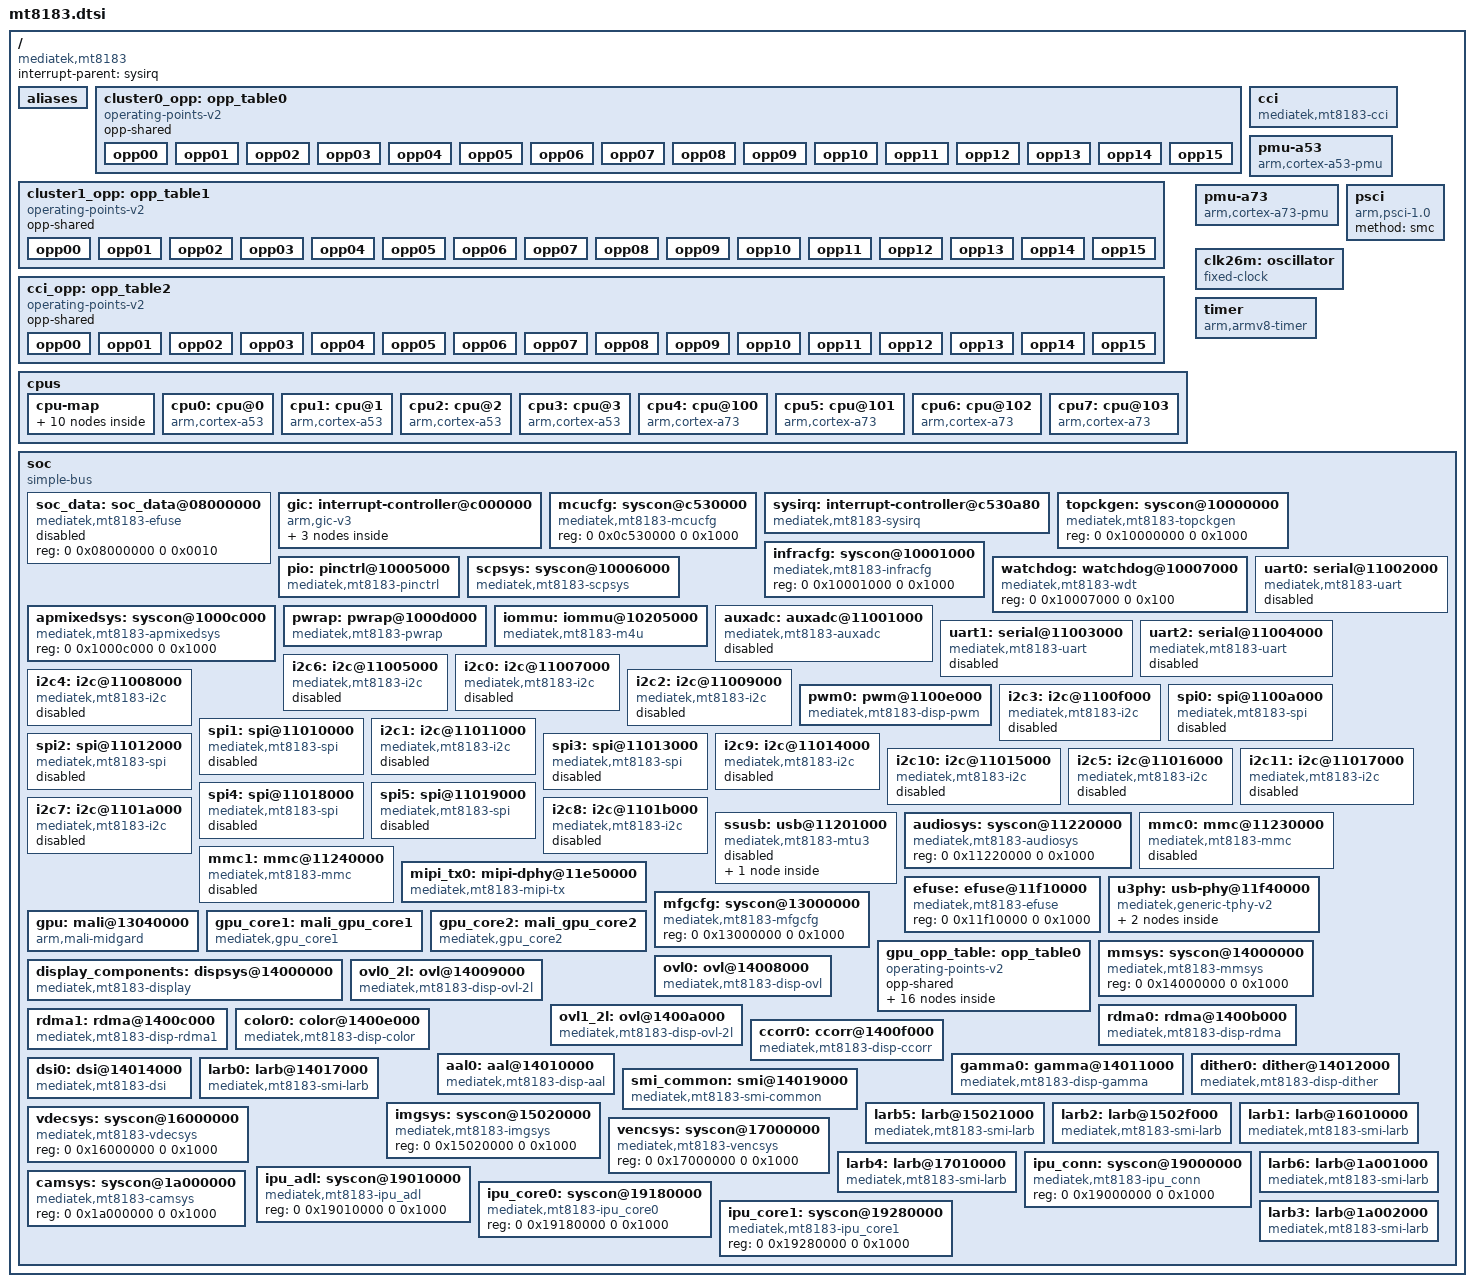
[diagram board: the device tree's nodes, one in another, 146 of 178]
// SPDX-License-Identifier: (GPL-2.0 OR MIT)
/*
 * Copyright (c) 2018 MediaTek Inc.
 * Author: Ben Ho <ben.ho@mediatek.com>
 *	   Erin Lo <erin.lo@mediatek.com>
 */

#include <dt-bindings/clock/mt8183-clk.h>
#include <dt-bindings/interrupt-controller/arm-gic.h>
#include <dt-bindings/interrupt-controller/irq.h>
#include <dt-bindings/memory/mt8183-larb-port.h>
#include <dt-bindings/phy/phy.h>
#include <dt-bindings/power/mt8183-power.h>
#include <dt-bindings/reset-controller/mt8183-resets.h>
#include "mt8183-pinfunc.h"

/ {
	compatible = "mediatek,mt8183";
	interrupt-parent = <&sysirq>;
	#address-cells = <2>;
	#size-cells = <2>;

	aliases {
		ovl0 = &ovl0;
		ovl_2l0 = &ovl0_2l;
		ovl_2l1 = &ovl1_2l;
		rdma0 = &rdma0;
		rdma1 = &rdma1;
		i2c0 = &i2c0;
		i2c1 = &i2c1;
		i2c2 = &i2c2;
		i2c3 = &i2c3;
		i2c4 = &i2c4;
		i2c5 = &i2c5;
		i2c6 = &i2c6;
		i2c7 = &i2c7;
		i2c8 = &i2c8;
		i2c9 = &i2c9;
		i2c10 = &i2c10;
		i2c11 = &i2c11;
	};

	cluster0_opp: opp_table0 {
		compatible = "operating-points-v2";
		opp-shared;
		opp00 {
			opp-hz = /bits/ 64 <793000000>;
			opp-microvolt = <650000>;
		};
		opp01 {
			opp-hz = /bits/ 64 <910000000>;
			opp-microvolt = <687500>;
		};
		opp02 {
			opp-hz = /bits/ 64 <1014000000>;
			opp-microvolt = <718750>;
		};
		opp03 {
			opp-hz = /bits/ 64 <1131000000>;
			opp-microvolt = <756250>;
		};
		opp04 {
			opp-hz = /bits/ 64 <1248000000>;
			opp-microvolt = <800000>;
		};
		opp05 {
			opp-hz = /bits/ 64 <1326000000>;
			opp-microvolt = <818750>;
		};
		opp06 {
			opp-hz = /bits/ 64 <1417000000>;
			opp-microvolt = <850000>;
		};
		opp07 {
			opp-hz = /bits/ 64 <1508000000>;
			opp-microvolt = <868750>;
		};
		opp08 {
			opp-hz = /bits/ 64 <1586000000>;
			opp-microvolt = <893750>;
		};
		opp09 {
			opp-hz = /bits/ 64 <1625000000>;
			opp-microvolt = <906250>;
		};
		opp10 {
			opp-hz = /bits/ 64 <1677000000>;
			opp-microvolt = <931250>;
		};
		opp11 {
			opp-hz = /bits/ 64 <1716000000>;
			opp-microvolt = <943750>;
		};
		opp12 {
			opp-hz = /bits/ 64 <1781000000>;
			opp-microvolt = <975000>;
		};
		opp13 {
			opp-hz = /bits/ 64 <1846000000>;
			opp-microvolt = <1000000>;
		};
		opp14 {
			opp-hz = /bits/ 64 <1924000000>;
			opp-microvolt = <1025000>;
		};
		opp15 {
			opp-hz = /bits/ 64 <1989000000>;
			opp-microvolt = <1050000>;
		};	};

	cluster1_opp: opp_table1 {
		compatible = "operating-points-v2";
		opp-shared;
		opp00 {
			opp-hz = /bits/ 64 <793000000>;
			opp-microvolt = <650000>;
		};
		opp01 {
			opp-hz = /bits/ 64 <910000000>;
			opp-microvolt = <675000>;
		};
		opp02 {
			opp-hz = /bits/ 64 <1014000000>;
			opp-microvolt = <700000>;
		};
		opp03 {
			opp-hz = /bits/ 64 <1131000000>;
			opp-microvolt = <725000>;
		};
		opp04 {
			opp-hz = /bits/ 64 <1248000000>;
			opp-microvolt = <750000>;
		};
		opp05 {
			opp-hz = /bits/ 64 <1326000000>;
			opp-microvolt = <775000>;
		};
		opp06 {
			opp-hz = /bits/ 64 <1417000000>;
			opp-microvolt = <800000>;
		};
		opp07 {
			opp-hz = /bits/ 64 <1508000000>;
			opp-microvolt = <825000>;
		};
		opp08 {
			opp-hz = /bits/ 64 <1586000000>;
			opp-microvolt = <850000>;
		};
		opp09 {
			opp-hz = /bits/ 64 <1625000000>;
			opp-microvolt = <862500>;
		};
		opp10 {
			opp-hz = /bits/ 64 <1677000000>;
			opp-microvolt = <881250>;
		};
		opp11 {
			opp-hz = /bits/ 64 <1716000000>;
			opp-microvolt = <900000>;
		};
		opp12 {
			opp-hz = /bits/ 64 <1781000000>;
			opp-microvolt = <925000>;
		};
		opp13 {
			opp-hz = /bits/ 64 <1846000000>;
			opp-microvolt = <950000>;
		};
		opp14 {
			opp-hz = /bits/ 64 <1924000000>;
			opp-microvolt = <975000>;
		};
		opp15 {
			opp-hz = /bits/ 64 <1989000000>;
			opp-microvolt = <1000000>;
		};
	};

	cci_opp: opp_table2 {
		compatible = "operating-points-v2";
		opp-shared;
		opp00 {
			opp-hz = /bits/ 64 <273000000>;
			opp-microvolt = <650000>;
		};
		opp01 {
			opp-hz = /bits/ 64 <338000000>;
			opp-microvolt = <687500>;
		};
		opp02 {
			opp-hz = /bits/ 64 <403000000>;
			opp-microvolt = <718750>;
		};
		opp03 {
			opp-hz = /bits/ 64 <463000000>;
			opp-microvolt = <756250>;
		};
		opp04 {
			opp-hz = /bits/ 64 <546000000>;
			opp-microvolt = <800000>;
		};
		opp05 {
			opp-hz = /bits/ 64 <624000000>;
			opp-microvolt = <818750>;
		};
		opp06 {
			opp-hz = /bits/ 64 <689000000>;
			opp-microvolt = <850000>;
		};
		opp07 {
			opp-hz = /bits/ 64 <767000000>;
			opp-microvolt = <868750>;
		};
		opp08 {
			opp-hz = /bits/ 64 <845000000>;
			opp-microvolt = <893750>;
		};
		opp09 {
			opp-hz = /bits/ 64 <871000000>;
			opp-microvolt = <906250>;
		};
		opp10 {
			opp-hz = /bits/ 64 <923000000>;
			opp-microvolt = <931250>;
		};
		opp11 {
			opp-hz = /bits/ 64 <962000000>;
			opp-microvolt = <943750>;
		};
		opp12 {
			opp-hz = /bits/ 64 <1027000000>;
			opp-microvolt = <975000>;
		};
		opp13 {
			opp-hz = /bits/ 64 <1092000000>;
			opp-microvolt = <1000000>;
		};
		opp14 {
			opp-hz = /bits/ 64 <1144000000>;
			opp-microvolt = <1025000>;
		};
		opp15 {
			opp-hz = /bits/ 64 <1196000000>;
			opp-microvolt = <1050000>;
		};
	};

	cci: cci {
		compatible = "mediatek,mt8183-cci";
		clocks = <&apmixedsys CLK_APMIXED_CCIPLL>;
		clock-names = "cci_clock";
		operating-points-v2 = <&cci_opp>;
	};

	cpus {
		#address-cells = <1>;
		#size-cells = <0>;

		cpu-map {
			cluster0 {
				core0 {
					cpu = <&cpu0>;
				};
				core1 {
					cpu = <&cpu1>;
				};
				core2 {
					cpu = <&cpu2>;
				};
				core3 {
					cpu = <&cpu3>;
				};
			};

			cluster1 {
				core0 {
					cpu = <&cpu4>;
				};
				core1 {
					cpu = <&cpu5>;
				};
				core2 {
					cpu = <&cpu6>;
				};
				core3 {
					cpu = <&cpu7>;
				};
			};
		};

		cpu0: cpu@0 {
			device_type = "cpu";
			compatible = "arm,cortex-a53";
			reg = <0x000>;
			enable-method = "psci";
			clocks = <&mcucfg CLK_MCU_MP0_SEL>,
				 <&topckgen CLK_TOP_ARMPLL_DIV_PLL1>;
			clock-names = "cpu", "intermediate";
			operating-points-v2 = <&cluster0_opp>;
		};

		cpu1: cpu@1 {
			device_type = "cpu";
			compatible = "arm,cortex-a53";
			reg = <0x001>;
			enable-method = "psci";
			clocks = <&mcucfg CLK_MCU_MP0_SEL>,
				 <&topckgen CLK_TOP_ARMPLL_DIV_PLL1>;
			clock-names = "cpu", "intermediate";
			operating-points-v2 = <&cluster0_opp>;
		};

		cpu2: cpu@2 {
			device_type = "cpu";
			compatible = "arm,cortex-a53";
			reg = <0x002>;
			enable-method = "psci";
			clocks = <&mcucfg CLK_MCU_MP0_SEL>,
				 <&topckgen CLK_TOP_ARMPLL_DIV_PLL1>;
			clock-names = "cpu", "intermediate";
			operating-points-v2 = <&cluster0_opp>;
		};

		cpu3: cpu@3 {
			device_type = "cpu";
			compatible = "arm,cortex-a53";
			reg = <0x003>;
			enable-method = "psci";
			clocks = <&mcucfg CLK_MCU_MP0_SEL>,
				 <&topckgen CLK_TOP_ARMPLL_DIV_PLL1>;
			clock-names = "cpu", "intermediate";
			operating-points-v2 = <&cluster0_opp>;
		};

		cpu4: cpu@100 {
			device_type = "cpu";
			compatible = "arm,cortex-a73";
			reg = <0x100>;
			enable-method = "psci";
			clocks = <&mcucfg CLK_MCU_MP2_SEL>,
				 <&topckgen CLK_TOP_ARMPLL_DIV_PLL1>;
			clock-names = "cpu", "intermediate";
			operating-points-v2 = <&cluster1_opp>;
		};

		cpu5: cpu@101 {
			device_type = "cpu";
			compatible = "arm,cortex-a73";
			reg = <0x101>;
			enable-method = "psci";
			clocks = <&mcucfg CLK_MCU_MP2_SEL>,
				 <&topckgen CLK_TOP_ARMPLL_DIV_PLL1>;
			clock-names = "cpu", "intermediate";
			operating-points-v2 = <&cluster1_opp>;
		};

		cpu6: cpu@102 {
			device_type = "cpu";
			compatible = "arm,cortex-a73";
			reg = <0x102>;
			enable-method = "psci";
			clocks = <&mcucfg CLK_MCU_MP2_SEL>,
				 <&topckgen CLK_TOP_ARMPLL_DIV_PLL1>;
			clock-names = "cpu", "intermediate";
			operating-points-v2 = <&cluster1_opp>;
		};

		cpu7: cpu@103 {
			device_type = "cpu";
			compatible = "arm,cortex-a73";
			reg = <0x103>;
			enable-method = "psci";
			clocks = <&mcucfg CLK_MCU_MP2_SEL>,
				 <&topckgen CLK_TOP_ARMPLL_DIV_PLL1>;
			clock-names = "cpu", "intermediate";
			operating-points-v2 = <&cluster1_opp>;
		};
	};

	pmu-a53 {
		compatible = "arm,cortex-a53-pmu";
		interrupt-parent = <&gic>;
		interrupts = <GIC_PPI 7 IRQ_TYPE_LEVEL_LOW &ppi_cluster0>;
	};

	pmu-a73 {
		compatible = "arm,cortex-a73-pmu";
		interrupt-parent = <&gic>;
		interrupts = <GIC_PPI 7 IRQ_TYPE_LEVEL_LOW &ppi_cluster1>;
	};

	psci {
		compatible      = "arm,psci-1.0";
		method          = "smc";
	};

	clk26m: oscillator {
		compatible = "fixed-clock";
		#clock-cells = <0>;
		clock-frequency = <26000000>;
		clock-output-names = "clk26m";
	};

	timer {
		compatible = "arm,armv8-timer";
		interrupt-parent = <&gic>;
		interrupts = <GIC_PPI 13 IRQ_TYPE_LEVEL_LOW 0>,
			     <GIC_PPI 14 IRQ_TYPE_LEVEL_LOW 0>,
			     <GIC_PPI 11 IRQ_TYPE_LEVEL_LOW 0>,
			     <GIC_PPI 10 IRQ_TYPE_LEVEL_LOW 0>;
	};

	soc {
		#address-cells = <2>;
		#size-cells = <2>;
		compatible = "simple-bus";
		ranges;

		soc_data: soc_data@08000000 {
			compatible = "mediatek,mt8183-efuse",
				     "mediatek,efuse";
			reg = <0 0x08000000 0 0x0010>;
			#address-cells = <1>;
			#size-cells = <1>;
			status = "disabled";
		};

		gic: interrupt-controller@c000000 {
			compatible = "arm,gic-v3";
			#interrupt-cells = <4>;
			interrupt-parent = <&gic>;
			interrupt-controller;
			reg = <0 0x0c000000 0 0x40000>,  /* GICD */
			      <0 0x0c100000 0 0x200000>, /* GICR */
			      <0 0x0c400000 0 0x2000>,   /* GICC */
			      <0 0x0c410000 0 0x1000>,   /* GICH */
			      <0 0x0c420000 0 0x2000>;   /* GICV */

			interrupts = <GIC_PPI 9 IRQ_TYPE_LEVEL_HIGH 0>;
			ppi-partitions {
				ppi_cluster0: interrupt-partition-0 {
					affinity = <&cpu0 &cpu1 &cpu2 &cpu3>;
				};
				ppi_cluster1: interrupt-partition-1 {
					affinity = <&cpu4 &cpu5 &cpu6 &cpu7>;
				};
			};
		};

		mcucfg: syscon@c530000 {
			compatible = "mediatek,mt8183-mcucfg", "syscon";
			reg = <0 0x0c530000 0 0x1000>;
			#clock-cells = <1>;
		};

		sysirq: interrupt-controller@c530a80 {
			compatible = "mediatek,mt8183-sysirq",
				     "mediatek,mt6577-sysirq";
			interrupt-controller;
			#interrupt-cells = <3>;
			interrupt-parent = <&gic>;
			reg = <0 0x0c530a80 0 0x50>;
		};

		topckgen: syscon@10000000 {
			compatible = "mediatek,mt8183-topckgen", "syscon";
			reg = <0 0x10000000 0 0x1000>;
			#clock-cells = <1>;
		};

		infracfg: syscon@10001000 {
			compatible = "mediatek,mt8183-infracfg", "syscon";
			reg = <0 0x10001000 0 0x1000>;
			#clock-cells = <1>;
			#reset-cells = <1>;
		};

		pio: pinctrl@10005000 {
			compatible = "mediatek,mt8183-pinctrl";
			reg = <0 0x10005000 0 0x1000>,
			      <0 0x11f20000 0 0x1000>,
			      <0 0x11e80000 0 0x1000>,
			      <0 0x11e70000 0 0x1000>,
			      <0 0x11e90000 0 0x1000>,
			      <0 0x11d30000 0 0x1000>,
			      <0 0x11d20000 0 0x1000>,
			      <0 0x11c50000 0 0x1000>,
			      <0 0x11f30000 0 0x1000>,
			      <0 0x1000b000 0 0x1000>;
			reg-names = "iocfg0", "iocfg1", "iocfg2",
				    "iocfg3", "iocfg4", "iocfg5",
				    "iocfg6", "iocfg7", "iocfg8",
				    "eint";
			gpio-controller;
			#gpio-cells = <2>;
			gpio-ranges = <&pio 0 0 192>;
			interrupt-controller;
			interrupts = <GIC_SPI 177 IRQ_TYPE_LEVEL_HIGH>;
			#interrupt-cells = <2>;
		};

		scpsys: syscon@10006000 {
			compatible = "mediatek,mt8183-scpsys", "syscon";
			#power-domain-cells = <1>;
			reg = <0 0x10006000 0 0x1000>;
			clocks = <&topckgen CLK_TOP_MUX_AUD_INTBUS>,
				 <&infracfg CLK_INFRA_AUDIO>,
				 <&infracfg CLK_INFRA_AUDIO_26M_BCLK>,
				 <&topckgen CLK_TOP_MUX_MFG>,
				 <&topckgen CLK_TOP_MUX_MM>,
				 <&topckgen CLK_TOP_MUX_CAM>,
				 <&topckgen CLK_TOP_MUX_IMG>,
				 <&topckgen CLK_TOP_MUX_IPU_IF>,
				 <&topckgen CLK_TOP_MUX_DSP>,
				 <&topckgen CLK_TOP_MUX_DSP1>,
				 <&topckgen CLK_TOP_MUX_DSP2>,
				 <&mmsys CLK_MM_SMI_COMMON>,
				 <&mmsys CLK_MM_SMI_LARB0>,
				 <&mmsys CLK_MM_SMI_LARB1>,
				 <&mmsys CLK_MM_GALS_COMM0>,
				 <&mmsys CLK_MM_GALS_COMM1>,
				 <&mmsys CLK_MM_GALS_CCU2MM>,
				 <&mmsys CLK_MM_GALS_IPU12MM>,
				 <&mmsys CLK_MM_GALS_IMG2MM>,
				 <&mmsys CLK_MM_GALS_CAM2MM>,
				 <&mmsys CLK_MM_GALS_IPU2MM>,
				 <&imgsys CLK_IMG_LARB5>,
				 <&imgsys CLK_IMG_LARB2>,
				 <&camsys CLK_CAM_LARB6>,
				 <&camsys CLK_CAM_LARB3>,
				 <&camsys CLK_CAM_SENINF>,
				 <&camsys CLK_CAM_CAMSV0>,
				 <&camsys CLK_CAM_CAMSV1>,
				 <&camsys CLK_CAM_CAMSV2>,
				 <&camsys CLK_CAM_CCU>,
				 <&ipu_conn CLK_IPU_CONN_IPU>,
				 <&ipu_conn CLK_IPU_CONN_AHB>,
				 <&ipu_conn CLK_IPU_CONN_AXI>,
				 <&ipu_conn CLK_IPU_CONN_ISP>,
				 <&ipu_conn CLK_IPU_CONN_CAM_ADL>,
				 <&ipu_conn CLK_IPU_CONN_IMG_ADL>;
			clock-names = "audio", "audio1", "audio2",
				      "mfg", "mm", "cam",
				      "isp", "vpu", "vpu1",
				      "vpu2", "vpu3", "mm-0",
				      "mm-1", "mm-2", "mm-3",
				      "mm-4", "mm-5", "mm-6",
				      "mm-7", "mm-8", "mm-9",
				      "isp-0", "isp-1", "cam-0",
				      "cam-1", "cam-2", "cam-3",
				      "cam-4", "cam-5", "cam-6",
				      "vpu-0", "vpu-1", "vpu-2",
				      "vpu-3", "vpu-4", "vpu-5";
			infracfg = <&infracfg>;
			smi_comm = <&smi_common>;
		};

		watchdog: watchdog@10007000 {
			compatible = "mediatek,mt8183-wdt",
				      "mediatek,mt6589-wdt";
			reg = <0 0x10007000 0 0x100>;
		};

		apmixedsys: syscon@1000c000 {
			compatible = "mediatek,mt8183-apmixedsys", "syscon";
			reg = <0 0x1000c000 0 0x1000>;
			#clock-cells = <1>;
		};

		pwrap: pwrap@1000d000 {
			compatible = "mediatek,mt8183-pwrap";
			reg = <0 0x1000d000 0 0x1000>;
			reg-names = "pwrap";
			interrupts = <GIC_SPI 209 IRQ_TYPE_LEVEL_HIGH>;
			clocks = <&topckgen CLK_TOP_MUX_PMICSPI>,
				 <&infracfg CLK_INFRA_PMIC_AP>;
			clock-names = "spi", "wrap";
		};

		iommu: iommu@10205000 {
			compatible = "mediatek,mt8183-m4u";
			reg = <0 0x10205000 0 0x1000>;
			interrupts = <GIC_SPI 166 IRQ_TYPE_LEVEL_LOW>;
			mediatek,larbs = <&larb0 &larb1 &larb2 &larb3
					  &larb4 &larb5 &larb6>;
			#iommu-cells = <1>;
		};

		auxadc: auxadc@11001000 {
			compatible = "mediatek,mt8183-auxadc",
				     "mediatek,mt8173-auxadc";
			reg = <0 0x11001000 0 0x1000>;
			clocks = <&infracfg CLK_INFRA_AUXADC>;
			clock-names = "main";
			#io-channel-cells = <1>;
			status = "disabled";
		};

		uart0: serial@11002000 {
			compatible = "mediatek,mt8183-uart",
				     "mediatek,mt6577-uart";
			reg = <0 0x11002000 0 0x1000>;
			interrupts = <GIC_SPI 91 IRQ_TYPE_LEVEL_LOW>;
			clocks = <&clk26m>, <&infracfg CLK_INFRA_UART0>;
			clock-names = "baud", "bus";
			status = "disabled";
		};

		uart1: serial@11003000 {
			compatible = "mediatek,mt8183-uart",
				     "mediatek,mt6577-uart";
			reg = <0 0x11003000 0 0x1000>;
			interrupts = <GIC_SPI 92 IRQ_TYPE_LEVEL_LOW>;
			clocks = <&clk26m>, <&infracfg CLK_INFRA_UART1>;
			clock-names = "baud", "bus";
			status = "disabled";
		};

		uart2: serial@11004000 {
			compatible = "mediatek,mt8183-uart",
				     "mediatek,mt6577-uart";
			reg = <0 0x11004000 0 0x1000>;
			interrupts = <GIC_SPI 93 IRQ_TYPE_LEVEL_LOW>;
			clocks = <&clk26m>, <&infracfg CLK_INFRA_UART2>;
			clock-names = "baud", "bus";
			status = "disabled";
		};

		i2c6: i2c@11005000 {
			compatible = "mediatek,mt8183-i2c";
			reg = <0 0x11005000 0 0x1000>,
				<0 0x11000600 0 0x80>;
			interrupts = <GIC_SPI 87 IRQ_TYPE_LEVEL_LOW>;
			clocks = <&infracfg CLK_INFRA_I2C6>,
				 <&infracfg CLK_INFRA_AP_DMA>;
			clock-names = "main", "dma";
			clock-div = <1>;
			#address-cells = <1>;
			#size-cells = <0>;
			status = "disabled";
		};

		i2c0: i2c@11007000 {
			compatible = "mediatek,mt8183-i2c";
			reg = <0 0x11007000 0 0x1000>,
				<0 0x11000080 0 0x80>;
			interrupts = <GIC_SPI 81 IRQ_TYPE_LEVEL_LOW>;
			clocks = <&infracfg CLK_INFRA_I2C0>,
				 <&infracfg CLK_INFRA_AP_DMA>;
			clock-names = "main", "dma";
			clock-div = <1>;
			#address-cells = <1>;
			#size-cells = <0>;
			status = "disabled";
		};

		i2c4: i2c@11008000 {
			compatible = "mediatek,mt8183-i2c";
			id = <4>;
			reg = <0 0x11008000 0 0x1000>,
				<0 0x11000100 0 0x80>;
			interrupts = <GIC_SPI 82 IRQ_TYPE_LEVEL_LOW>;
			clocks = <&infracfg CLK_INFRA_I2C1>,
				 <&infracfg CLK_INFRA_AP_DMA>,
				 <&infracfg CLK_INFRA_I2C1_ARBITER>;
			clock-names = "main", "dma","arb";
			clock-div = <1>;
			#address-cells = <1>;
			#size-cells = <0>;
			status = "disabled";
		};

		i2c2: i2c@11009000 {
			compatible = "mediatek,mt8183-i2c";
			reg = <0 0x11009000 0 0x1000>,
				<0 0x11000280 0 0x80>;
			interrupts = <GIC_SPI 83 IRQ_TYPE_LEVEL_LOW>;
			clocks = <&infracfg CLK_INFRA_I2C2>,
				 <&infracfg CLK_INFRA_AP_DMA>,
				 <&infracfg CLK_INFRA_I2C2_ARBITER>;
			clock-names = "main", "dma", "arb";
			clock-div = <1>;
			#address-cells = <1>;
			#size-cells = <0>;
			status = "disabled";
		};

		pwm0: pwm@1100e000 {
			compatible = "mediatek,mt8183-disp-pwm";
			reg = <0 0x1100e000 0 0x1000>;
			interrupts = <GIC_SPI 128 IRQ_TYPE_LEVEL_LOW>;
			power-domains = <&scpsys MT8183_POWER_DOMAIN_DISP>;
			#pwm-cells = <2>;
			clocks = <&topckgen CLK_TOP_MUX_DISP_PWM>,
					<&infracfg CLK_INFRA_DISP_PWM>;
			clock-names = "main", "mm";
		};

		i2c3: i2c@1100f000 {
			compatible = "mediatek,mt8183-i2c";
			reg = <0 0x1100f000 0 0x1000>,
				<0 0x11000400 0 0x80>;
			interrupts = <GIC_SPI 84 IRQ_TYPE_LEVEL_LOW>;
			clocks = <&infracfg CLK_INFRA_I2C3>,
				 <&infracfg CLK_INFRA_AP_DMA>;
			clock-names = "main", "dma";
			clock-div = <1>;
			#address-cells = <1>;
			#size-cells = <0>;
			status = "disabled";
		};

		spi0: spi@1100a000 {
			compatible = "mediatek,mt8183-spi";
			#address-cells = <1>;
			#size-cells = <0>;
			reg = <0 0x1100a000 0 0x1000>;
			interrupts = <GIC_SPI 120 IRQ_TYPE_LEVEL_LOW>;
			clocks = <&topckgen CLK_TOP_SYSPLL_D5_D2>,
				 <&topckgen CLK_TOP_MUX_SPI>,
				 <&infracfg CLK_INFRA_SPI0>;
			clock-names = "parent-clk", "sel-clk", "spi-clk";
			status = "disabled";
		};

		spi1: spi@11010000 {
			compatible = "mediatek,mt8183-spi";
			#address-cells = <1>;
			#size-cells = <0>;
			reg = <0 0x11010000 0 0x1000>;
			interrupts = <GIC_SPI 124 IRQ_TYPE_LEVEL_LOW>;
			clocks = <&topckgen CLK_TOP_SYSPLL_D5_D2>,
				 <&topckgen CLK_TOP_MUX_SPI>,
				 <&infracfg CLK_INFRA_SPI1>;
			clock-names = "parent-clk", "sel-clk", "spi-clk";
			status = "disabled";
		};

		i2c1: i2c@11011000 {
			compatible = "mediatek,mt8183-i2c";
			reg = <0 0x11011000 0 0x1000>,
				<0 0x11000480 0 0x80>;
			interrupts = <GIC_SPI 85 IRQ_TYPE_LEVEL_LOW>;
			clocks = <&infracfg CLK_INFRA_I2C4>,
				 <&infracfg CLK_INFRA_AP_DMA>;
			clock-names = "main", "dma";
			clock-div = <1>;
			#address-cells = <1>;
			#size-cells = <0>;
			status = "disabled";
		};

		spi2: spi@11012000 {
			compatible = "mediatek,mt8183-spi";
			#address-cells = <1>;
			#size-cells = <0>;
			reg = <0 0x11012000 0 0x1000>;
			interrupts = <GIC_SPI 129 IRQ_TYPE_LEVEL_LOW>;
			clocks = <&topckgen CLK_TOP_SYSPLL_D5_D2>,
				 <&topckgen CLK_TOP_MUX_SPI>,
				 <&infracfg CLK_INFRA_SPI2>;
			clock-names = "parent-clk", "sel-clk", "spi-clk";
			status = "disabled";
		};

		spi3: spi@11013000 {
			compatible = "mediatek,mt8183-spi";
			#address-cells = <1>;
			#size-cells = <0>;
			reg = <0 0x11013000 0 0x1000>;
			interrupts = <GIC_SPI 130 IRQ_TYPE_LEVEL_LOW>;
			clocks = <&topckgen CLK_TOP_SYSPLL_D5_D2>,
				 <&topckgen CLK_TOP_MUX_SPI>,
				 <&infracfg CLK_INFRA_SPI3>;
			clock-names = "parent-clk", "sel-clk", "spi-clk";
			status = "disabled";
		};

		i2c9: i2c@11014000 {
			compatible = "mediatek,mt8183-i2c";
			reg = <0 0x11014000 0 0x1000>,
				<0 0x11000180 0 0x80>;
			interrupts = <GIC_SPI 131 IRQ_TYPE_LEVEL_LOW>;
			clocks = <&infracfg CLK_INFRA_I2C1_IMM>,
				 <&infracfg CLK_INFRA_AP_DMA>,
				 <&infracfg CLK_INFRA_I2C1_ARBITER>;
			clock-names = "main", "dma", "arb";
			clock-div = <1>;
			#address-cells = <1>;
			#size-cells = <0>;
			status = "disabled";
		};

		i2c10: i2c@11015000 {
			compatible = "mediatek,mt8183-i2c";
			reg = <0 0x11015000 0 0x1000>,
				<0 0x11000300 0 0x80>;
			interrupts = <GIC_SPI 132 IRQ_TYPE_LEVEL_LOW>;
			clocks = <&infracfg CLK_INFRA_I2C2_IMM>,
				 <&infracfg CLK_INFRA_AP_DMA>,
				 <&infracfg CLK_INFRA_I2C2_ARBITER>;
			clock-names = "main", "dma", "arb";
			clock-div = <1>;
			#address-cells = <1>;
			#size-cells = <0>;
			status = "disabled";
		};

		i2c5: i2c@11016000 {
			compatible = "mediatek,mt8183-i2c";
			reg = <0 0x11016000 0 0x1000>,
				<0 0x11000500 0 0x80>;
			interrupts = <GIC_SPI 86 IRQ_TYPE_LEVEL_LOW>;
			clocks = <&infracfg CLK_INFRA_I2C5>,
				 <&infracfg CLK_INFRA_AP_DMA>,
				 <&infracfg CLK_INFRA_I2C5_ARBITER>;
			clock-names = "main", "dma", "arb";
			clock-div = <1>;
			#address-cells = <1>;
			#size-cells = <0>;
			status = "disabled";
		};

		i2c11: i2c@11017000 {
			compatible = "mediatek,mt8183-i2c";
			reg = <0 0x11017000 0 0x1000>,
				<0 0x11000580 0 0x80>;
			interrupts = <GIC_SPI 133 IRQ_TYPE_LEVEL_LOW>;
			clocks = <&infracfg CLK_INFRA_I2C5_IMM>,
				 <&infracfg CLK_INFRA_AP_DMA>,
				 <&infracfg CLK_INFRA_I2C5_ARBITER>;
			clock-names = "main", "dma", "arb";
			clock-div = <1>;
			#address-cells = <1>;
			#size-cells = <0>;
			status = "disabled";
		};

		spi4: spi@11018000 {
			compatible = "mediatek,mt8183-spi";
			#address-cells = <1>;
			#size-cells = <0>;
			reg = <0 0x11018000 0 0x1000>;
			interrupts = <GIC_SPI 134 IRQ_TYPE_LEVEL_LOW>;
			clocks = <&topckgen CLK_TOP_SYSPLL_D5_D2>,
				 <&topckgen CLK_TOP_MUX_SPI>,
				 <&infracfg CLK_INFRA_SPI4>;
			clock-names = "parent-clk", "sel-clk", "spi-clk";
			status = "disabled";
		};

		spi5: spi@11019000 {
			compatible = "mediatek,mt8183-spi";
			#address-cells = <1>;
			#size-cells = <0>;
			reg = <0 0x11019000 0 0x1000>;
			interrupts = <GIC_SPI 135 IRQ_TYPE_LEVEL_LOW>;
			clocks = <&topckgen CLK_TOP_SYSPLL_D5_D2>,
				 <&topckgen CLK_TOP_MUX_SPI>,
				 <&infracfg CLK_INFRA_SPI5>;
			clock-names = "parent-clk", "sel-clk", "spi-clk";
			status = "disabled";
		};

		i2c7: i2c@1101a000 {
			compatible = "mediatek,mt8183-i2c";
			reg = <0 0x1101a000 0 0x1000>,
				<0 0x11000680 0 0x80>;
			interrupts = <GIC_SPI 88 IRQ_TYPE_LEVEL_LOW>;
			clocks = <&infracfg CLK_INFRA_I2C7>,
				 <&infracfg CLK_INFRA_AP_DMA>;
			clock-names = "main", "dma";
			clock-div = <1>;
			#address-cells = <1>;
			#size-cells = <0>;
			status = "disabled";
		};

		i2c8: i2c@1101b000 {
			compatible = "mediatek,mt8183-i2c";
			reg = <0 0x1101b000 0 0x1000>,
				<0 0x11000700 0 0x80>;
			interrupts = <GIC_SPI 89 IRQ_TYPE_LEVEL_LOW>;
			clocks = <&infracfg CLK_INFRA_I2C8>,
				 <&infracfg CLK_INFRA_AP_DMA>;
			clock-names = "main", "dma";
			clock-div = <1>;
			#address-cells = <1>;
			#size-cells = <0>;
			status = "disabled";
		};

		ssusb: usb@11201000 {
			compatible ="mediatek,mt8183-mtu3", "mediatek,mtu3";
			reg = <0 0x11201000 0 0x2e00>,
			      <0 0x11203e00 0 0x0100>;
			reg-names = "mac", "ippc";
			interrupts = <GIC_SPI 72 IRQ_TYPE_LEVEL_LOW>;
			phys = <&u2port0 PHY_TYPE_USB2>;
			clocks = <&infracfg CLK_INFRA_UNIPRO_SCK>,
				 <&infracfg CLK_INFRA_USB>;
			clock-names = "sys_ck", "ref_ck";
			#address-cells = <2>;
			#size-cells = <2>;
			ranges;
			status = "disabled";

			usb_host: xhci@11200000 {
				compatible = "mediatek,mtk-xhci";
				reg = <0 0x11200000 0 0x1000>;
				reg-names = "mac";
				interrupts = <GIC_SPI 73 IRQ_TYPE_LEVEL_LOW>;
				clocks = <&infracfg CLK_INFRA_UNIPRO_SCK>,
					 <&infracfg CLK_INFRA_USB>;
				clock-names = "sys_ck", "ref_ck";
				status = "disabled";
			};
		};

		audiosys: syscon@11220000 {
			compatible = "mediatek,mt8183-audiosys", "syscon";
			reg = <0 0x11220000 0 0x1000>;
			#clock-cells = <1>;
		};

		mmc0: mmc@11230000 {
			compatible = "mediatek,mt8183-mmc";
			reg = <0 0x11230000 0 0x1000>,
			      <0 0x11f50000 0 0x1000>;
			interrupts = <GIC_SPI 77 IRQ_TYPE_LEVEL_LOW>;
			clocks = <&topckgen CLK_TOP_MUX_MSDC50_0>,
				 <&infracfg CLK_INFRA_MSDC0>,
				 <&infracfg CLK_INFRA_MSDC0_SCK>;
			clock-names = "source", "hclk", "source_cg";
			status = "disabled";
		};

		mmc1: mmc@11240000 {
			compatible = "mediatek,mt8183-mmc";
			reg = <0 0x11240000 0 0x1000>,
			      <0 0x11e10000 0 0x1000>;
			interrupts = <GIC_SPI 78 IRQ_TYPE_LEVEL_LOW>;
			clocks = <&topckgen CLK_TOP_MUX_MSDC30_1>,
				 <&infracfg CLK_INFRA_MSDC1>,
				 <&infracfg CLK_INFRA_MSDC1_SCK>;
			clock-names = "source", "hclk", "source_cg";
			status = "disabled";
		};

		mipi_tx0: mipi-dphy@11e50000 {
			compatible = "mediatek,mt8183-mipi-tx";
			reg = <0 0x11e50000 0 0x1000>;
			clocks = <&apmixedsys CLK_APMIXED_MIPID0_26M>;
			clock-names = "ref_clk";
			#clock-cells = <0>;
			#phy-cells = <0>;
			clock-output-names = "mipi_tx0_pll";
		};

		efuse: efuse@11f10000 {
			compatible = "mediatek,mt8183-efuse",
				     "mediatek,efuse";
			reg = <0 0x11f10000 0 0x1000>;
		};

		u3phy: usb-phy@11f40000 {
			compatible = "mediatek,generic-tphy-v2";
			#address-cells = <2>;
			#size-cells = <2>;
			ranges;
			status = "okay";

			u2port0: usb-phy@11f40000 {
				reg = <0 0x11f40000 0 0x700>;
				clocks = <&clk26m>;
				clock-names = "ref";
				#phy-cells = <1>;
				status = "okay";
			};

			u3port0: usb-phy@11f40700 {
				reg = <0 0x11f40700 0 0x900>;
				clocks = <&clk26m>;
				clock-names = "ref";
				#phy-cells = <1>;
				status = "okay";
			};
		};

		mfgcfg: syscon@13000000 {
			compatible = "mediatek,mt8183-mfgcfg", "syscon";
			reg = <0 0x13000000 0 0x1000>;
			#clock-cells = <1>;
		};

		gpu: mali@13040000 {
			compatible = "arm,mali-midgard";
			reg = <0 0x13040000 0 0x4000>;
			interrupts =
				<GIC_SPI 278 IRQ_TYPE_LEVEL_LOW>,
				<GIC_SPI 279 IRQ_TYPE_LEVEL_LOW>,
				<GIC_SPI 280 IRQ_TYPE_LEVEL_LOW>;
			interrupt-names = "GPU", "MMU", "JOB";

			clocks =
				<&topckgen CLK_TOP_MFGPLL_CK>,
				<&topckgen CLK_TOP_MUX_MFG>,
				<&clk26m>,
				<&mfgcfg CLK_MFG_BG3D>;
			clock-names =
				"clk_main_parent",
				"clk_mux",
				"clk_sub_parent",
				"subsys_mfg_cg";

			power-domains = <&scpsys MT8183_POWER_DOMAIN_MFG_CORE0>;

			#cooling-cells = <2>;
			cooling-min-level = <0>;
			cooling-max-level = <15>;
		};

		gpu_core1: mali_gpu_core1 {
			compatible = "mediatek,gpu_core1";
			power-domains = <&scpsys MT8183_POWER_DOMAIN_MFG_CORE1>;
		};

		gpu_core2: mali_gpu_core2 {
			compatible = "mediatek,gpu_core2";
			power-domains = <&scpsys MT8183_POWER_DOMAIN_MFG_2D>;
		};

		gpu_opp_table: opp_table0 {
			compatible = "operating-points-v2", "operating-points-v2-mali";
			opp-shared;

			opp-300000000 {
				opp-hz = /bits/ 64 <300000000>;
				opp-microvolt = <625000>, /* Supply 0 */
						<850000>; /* Supply 1 */
				opp-core-mask = /bits/ 64 <0xf>;
			};

			opp-320000000 {
				opp-hz = /bits/ 64 <320000000>;
				opp-microvolt = <631250>, /* Supply 0 */
						<850000>; /* Supply 1 */
				opp-core-mask = /bits/ 64 <0xf>;
			};

			opp-340000000 {
				opp-hz = /bits/ 64 <340000000>;
				opp-microvolt = <637500>, /* Supply 0 */
						<850000>; /* Supply 1 */
				opp-core-mask = /bits/ 64 <0xf>;
			};

			opp-360000000 {
				opp-hz = /bits/ 64 <360000000>;
				opp-microvolt = <643750>, /* Supply 0 */
						<850000>; /* Supply 1 */
				opp-core-mask = /bits/ 64 <0xf>;
			};

			opp-380000000 {
				opp-hz = /bits/ 64 <380000000>;
				opp-microvolt = <650000>, /* Supply 0 */
						<850000>; /* Supply 1 */
				opp-core-mask = /bits/ 64 <0xf>;
			};

			opp-400000000 {
				opp-hz = /bits/ 64 <400000000>;
				opp-microvolt = <656250>, /* Supply 0 */
						<850000>; /* Supply 1 */
				opp-core-mask = /bits/ 64 <0xf>;
			};

			opp-420000000 {
				opp-hz = /bits/ 64 <420000000>;
				opp-microvolt = <662500>, /* Supply 0 */
						<850000>; /* Supply 1 */
				opp-core-mask = /bits/ 64 <0xf>;
			};

			opp-460000000 {
				opp-hz = /bits/ 64 <460000000>;
				opp-microvolt = <675000>, /* Supply 0 */
						<850000>; /* Supply 1 */
				opp-core-mask = /bits/ 64 <0xf>;
			};

			opp-500000000 {
				opp-hz = /bits/ 64 <500000000>;
				opp-microvolt = <687500>, /* Supply 0 */
						<850000>; /* Supply 1 */
				opp-core-mask = /bits/ 64 <0xf>;
			};

			opp-540000000 {
				opp-hz = /bits/ 64 <540000000>;
				opp-microvolt = <700000>, /* Supply 0 */
						<850000>; /* Supply 1 */
				opp-core-mask = /bits/ 64 <0xf>;
			};

			opp-580000000 {
				opp-hz = /bits/ 64 <580000000>;
				opp-microvolt = <712500>, /* Supply 0 */
						<850000>; /* Supply 1 */
				opp-core-mask = /bits/ 64 <0xf>;
			};

			opp-620000000 {
				opp-hz = /bits/ 64 <620000000>;
				opp-microvolt = <725000>, /* Supply 0 */
						<850000>; /* Supply 1 */
				opp-core-mask = /bits/ 64 <0xf>;
			};

			opp-653000000 {
				opp-hz = /bits/ 64 <653000000>;
				opp-microvolt = <743750>, /* Supply 0 */
						<850000>; /* Supply 1 */
				opp-core-mask = /bits/ 64 <0xf>;
			};

			opp-698000000 {
				opp-hz = /bits/ 64 <698000000>;
				opp-microvolt = <768750>, /* Supply 0 */
						<868750>; /* Supply 1 */
				opp-core-mask = /bits/ 64 <0xf>;
			};

			opp-743000000 {
				opp-hz = /bits/ 64 <743000000>;
				opp-microvolt = <793750>, /* Supply 0 */
						<893750>; /* Supply 1 */
				opp-core-mask = /bits/ 64 <0xf>;
			};

			opp-800000000 {
				opp-hz = /bits/ 64 <800000000>;
				opp-microvolt = <825000>, /* Supply 0 */
						<925000>; /* Supply 1 */
				opp-core-mask = /bits/ 64 <0xf>;
			};
		};

		mmsys: syscon@14000000 {
			compatible = "mediatek,mt8183-mmsys", "syscon";
			reg = <0 0x14000000 0 0x1000>;
			#clock-cells = <1>;
		};

		display_components: dispsys@14000000 {
			compatible = "mediatek,mt8183-display";
			reg = <0 0x14000000 0 0x1000>;
			power-domains = <&scpsys MT8183_POWER_DOMAIN_DISP>;
		};

		ovl0: ovl@14008000 {
			compatible = "mediatek,mt8183-disp-ovl";
			reg = <0 0x14008000 0 0x1000>;
			interrupts = <GIC_SPI 225 IRQ_TYPE_LEVEL_LOW>;
			power-domains = <&scpsys MT8183_POWER_DOMAIN_DISP>;
			clocks = <&mmsys CLK_MM_DISP_OVL0>;
			iommus = <&iommu M4U_PORT_DISP_OVL0>;
			mediatek,larb = <&larb0>;
		};

		ovl0_2l: ovl@14009000 {
			compatible = "mediatek,mt8183-disp-ovl-2l";
			reg = <0 0x14009000 0 0x1000>;
			interrupts = <GIC_SPI 226 IRQ_TYPE_LEVEL_LOW>;
			power-domains = <&scpsys MT8183_POWER_DOMAIN_DISP>;
			clocks = <&mmsys CLK_MM_DISP_OVL0_2L>;
			iommus = <&iommu M4U_PORT_DISP_2L_OVL0_LARB0>;
			mediatek,larb = <&larb0>;
		};

		ovl1_2l: ovl@1400a000 {
			compatible = "mediatek,mt8183-disp-ovl-2l";
			reg = <0 0x1400a000 0 0x1000>;
			interrupts = <GIC_SPI 227 IRQ_TYPE_LEVEL_LOW>;
			power-domains = <&scpsys MT8183_POWER_DOMAIN_DISP>;
			clocks = <&mmsys CLK_MM_DISP_OVL1_2L>;
			iommus = <&iommu M4U_PORT_DISP_2L_OVL1_LARB0>;
			mediatek,larb = <&larb0>;
		};

		rdma0: rdma@1400b000 {
			compatible = "mediatek,mt8183-disp-rdma";
			reg = <0 0x1400b000 0 0x1000>;
			interrupts = <GIC_SPI 228 IRQ_TYPE_LEVEL_LOW>;
			power-domains = <&scpsys MT8183_POWER_DOMAIN_DISP>;
			clocks = <&mmsys CLK_MM_DISP_RDMA0>;
			iommus = <&iommu M4U_PORT_DISP_RDMA0>;
			mediatek,larb = <&larb0>;
		};

		rdma1: rdma@1400c000 {
			compatible = "mediatek,mt8183-disp-rdma1";
			reg = <0 0x1400c000 0 0x1000>;
			interrupts = <GIC_SPI 229 IRQ_TYPE_LEVEL_LOW>;
			power-domains = <&scpsys MT8183_POWER_DOMAIN_DISP>;
			clocks = <&mmsys CLK_MM_DISP_RDMA1>;
			iommus = <&iommu M4U_PORT_DISP_RDMA1>;
			mediatek,larb = <&larb0>;
		};

		color0: color@1400e000 {
			compatible = "mediatek,mt8183-disp-color",
				     "mediatek,mt8173-disp-color";
			reg = <0 0x1400e000 0 0x1000>;
			interrupts = <GIC_SPI 231 IRQ_TYPE_LEVEL_LOW>;
			power-domains = <&scpsys MT8183_POWER_DOMAIN_DISP>;
			clocks = <&mmsys CLK_MM_DISP_COLOR0>;
		};

		ccorr0: ccorr@1400f000 {
			compatible = "mediatek,mt8183-disp-ccorr";
			reg = <0 0x1400f000 0 0x1000>;
			interrupts = <GIC_SPI 232 IRQ_TYPE_LEVEL_LOW>;
			power-domains = <&scpsys MT8183_POWER_DOMAIN_DISP>;
			clocks = <&mmsys CLK_MM_DISP_CCORR0>;
		};

		aal0: aal@14010000 {
			compatible = "mediatek,mt8183-disp-aal",
				     "mediatek,mt8173-disp-aal";
			reg = <0 0x14010000 0 0x1000>;
			interrupts = <GIC_SPI 233 IRQ_TYPE_LEVEL_LOW>;
			power-domains = <&scpsys MT8183_POWER_DOMAIN_DISP>;
			clocks = <&mmsys CLK_MM_DISP_AAL0>;
		};

		gamma0: gamma@14011000 {
			compatible = "mediatek,mt8183-disp-gamma",
				     "mediatek,mt8173-disp-gamma";
			reg = <0 0x14011000 0 0x1000>;
			interrupts = <GIC_SPI 234 IRQ_TYPE_LEVEL_LOW>;
			power-domains = <&scpsys MT8183_POWER_DOMAIN_DISP>;
			clocks = <&mmsys CLK_MM_DISP_GAMMA0>;
		};

		dither0: dither@14012000 {
			compatible = "mediatek,mt8183-disp-dither";
			reg = <0 0x14012000 0 0x1000>;
			interrupts = <GIC_SPI 235 IRQ_TYPE_LEVEL_LOW>;
			power-domains = <&scpsys MT8183_POWER_DOMAIN_DISP>;
			clocks = <&mmsys CLK_MM_DISP_DITHER0>;
		};

		dsi0: dsi@14014000 {
			compatible = "mediatek,mt8183-dsi";
			reg = <0 0x14014000 0 0x1000>;
			interrupts = <GIC_SPI 236 IRQ_TYPE_LEVEL_LOW>;
			power-domains = <&scpsys MT8183_POWER_DOMAIN_DISP>;
			mediatek,syscon-dsi = <&mmsys 0x140>;
			clocks = <&mmsys CLK_MM_DSI0_MM>,
				<&mmsys CLK_MM_DSI0_IF>,
				<&mipi_tx0>;
			clock-names = "engine", "digital", "hs";
			phys = <&mipi_tx0>;
			phy-names = "dphy";
		};

		larb0: larb@14017000 {
			compatible = "mediatek,mt8183-smi-larb";
			reg = <0 0x14017000 0 0x1000>;
			mediatek,smi = <&smi_common>;
			clocks = <&mmsys CLK_MM_SMI_LARB0>,
				 <&mmsys CLK_MM_SMI_LARB0>;
			power-domains = <&scpsys MT8183_POWER_DOMAIN_DISP>;
			clock-names = "apb", "smi";
		};

		smi_common: smi@14019000 {
			compatible = "mediatek,mt8183-smi-common", "syscon";
			reg = <0 0x14019000 0 0x1000>;
			clocks = <&mmsys CLK_MM_SMI_COMMON>,
				 <&mmsys CLK_MM_SMI_COMMON>,
				 <&mmsys CLK_MM_GALS_COMM0>,
				 <&mmsys CLK_MM_GALS_COMM1>;
			clock-names = "apb", "smi", "gals0", "gals1";
			power-domains = <&scpsys MT8183_POWER_DOMAIN_DISP>;
		};

		imgsys: syscon@15020000 {
			compatible = "mediatek,mt8183-imgsys", "syscon";
			reg = <0 0x15020000 0 0x1000>;
			#clock-cells = <1>;
		};

		larb5: larb@15021000 {
			compatible = "mediatek,mt8183-smi-larb";
			reg = <0 0x15021000 0 0x1000>;
			mediatek,smi = <&smi_common>;
			clocks = <&imgsys CLK_IMG_LARB5>, <&imgsys CLK_IMG_LARB5>,
				 <&mmsys CLK_MM_GALS_IMG2MM>;
			clock-names = "apb", "smi", "gals";
			power-domains = <&scpsys MT8183_POWER_DOMAIN_ISP>;
		};

		larb2: larb@1502f000 {
			compatible = "mediatek,mt8183-smi-larb";
			reg = <0 0x1502f000 0 0x1000>;
			mediatek,smi = <&smi_common>;
			clocks = <&imgsys CLK_IMG_LARB2>, <&imgsys CLK_IMG_LARB2>,
				 <&mmsys CLK_MM_GALS_IPU2MM>;
			clock-names = "apb", "smi", "gals";
			power-domains = <&scpsys MT8183_POWER_DOMAIN_ISP>;
		};

		vdecsys: syscon@16000000 {
			compatible = "mediatek,mt8183-vdecsys", "syscon";
			reg = <0 0x16000000 0 0x1000>;
			#clock-cells = <1>;
		};

		larb1: larb@16010000 {
			compatible = "mediatek,mt8183-smi-larb";
			reg = <0 0x16010000 0 0x1000>;
			mediatek,smi = <&smi_common>;
			clocks = <&vdecsys CLK_VDEC_VDEC>, <&vdecsys CLK_VDEC_LARB1>;
			clock-names = "apb", "smi";
			power-domains = <&scpsys MT8183_POWER_DOMAIN_VDEC>;
		};

		vencsys: syscon@17000000 {
			compatible = "mediatek,mt8183-vencsys", "syscon";
			reg = <0 0x17000000 0 0x1000>;
			#clock-cells = <1>;
		};

		larb4: larb@17010000 {
			compatible = "mediatek,mt8183-smi-larb";
			reg = <0 0x17010000 0 0x1000>;
			mediatek,smi = <&smi_common>;
			clocks = <&vencsys CLK_VENC_LARB>,
				 <&vencsys CLK_VENC_LARB>;
			clock-names = "apb", "smi";
			power-domains = <&scpsys MT8183_POWER_DOMAIN_VENC>;
		};

		ipu_conn: syscon@19000000 {
			compatible = "mediatek,mt8183-ipu_conn", "syscon";
			reg = <0 0x19000000 0 0x1000>;
			#clock-cells = <1>;
		};

		ipu_adl: syscon@19010000 {
			compatible = "mediatek,mt8183-ipu_adl", "syscon";
			reg = <0 0x19010000 0 0x1000>;
			#clock-cells = <1>;
		};

		ipu_core0: syscon@19180000 {
			compatible = "mediatek,mt8183-ipu_core0", "syscon";
			reg = <0 0x19180000 0 0x1000>;
			#clock-cells = <1>;
		};

		ipu_core1: syscon@19280000 {
			compatible = "mediatek,mt8183-ipu_core1", "syscon";
			reg = <0 0x19280000 0 0x1000>;
			#clock-cells = <1>;
		};

		camsys: syscon@1a000000 {
			compatible = "mediatek,mt8183-camsys", "syscon";
			reg = <0 0x1a000000 0 0x1000>;
			#clock-cells = <1>;
		};

		larb6: larb@1a001000 {
			compatible = "mediatek,mt8183-smi-larb";
			reg = <0 0x1a001000 0 0x1000>;
			mediatek,smi = <&smi_common>;
			clocks = <&camsys CLK_CAM_LARB6>, <&camsys CLK_CAM_LARB6>,
				 <&mmsys CLK_MM_GALS_CAM2MM>;
			clock-names = "apb", "smi", "gals";
			power-domains = <&scpsys MT8183_POWER_DOMAIN_CAM>;
		};

		larb3: larb@1a002000 {
			compatible = "mediatek,mt8183-smi-larb";
			reg = <0 0x1a002000 0 0x1000>;
			mediatek,smi = <&smi_common>;
			clocks = <&camsys CLK_CAM_LARB3>, <&camsys CLK_CAM_LARB3>,
				 <&mmsys CLK_MM_GALS_IPU12MM>;
			clock-names = "apb", "smi", "gals";
			power-domains = <&scpsys MT8183_POWER_DOMAIN_CAM>;
		};
	};
};
